# RL6955_IP_SVD register map
Vendor: Realtek
Registers are 32-bit, read-write, reset 0x0 unless marked. A register's access mark holds for its fields unless they carry their own. Offsets are from the block's base; [hi:lo] are bit positions; {n}, {i} and the like mark numbered series.

## CMP_REG
Base 0x4100A800
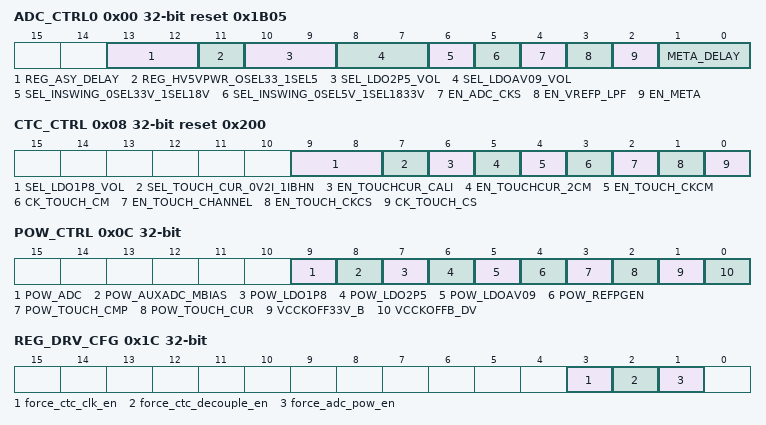
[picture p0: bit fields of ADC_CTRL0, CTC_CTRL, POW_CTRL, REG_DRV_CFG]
0x00 ADC_CTRL0 reset 0x1B05
  [13:12] REG_ASY_DELAY — Asy SAR ADC compare time. Control the delay of the comparator. If the comparator fails to produce a result for a long time, it will force the output of the result. 00:Fast; 01: 10: 11:Slow:
  [11] REG_HV5VPWR_OSEL33_1SEL5 — This Reg is used to inform Analog HV5V's PAD whether it is a true 5V voltage. It is flexible for some applications where the 5V PAD is connected to 3.3V. HV5V PAD power is 3.3V or 5V signal to Aphy.
  [10:9] SEL_LDO2P5_VOL — 00:2.125V 01:2.25V 10:2.375V 11:2.50V AIF default 01:2.25V
  [8:7] SEL_LDOAV09_VOL — AUX ADC 0.9V LDO voltage: 00:0.85V 01:0.9V 10:0.95V (default) 11:1.0V AIF default 10:0.95V;
  [6] SEL_INSWING_0SEL33V_1SEL18V — 0:ADC Input Full swing is 3.3V; 1:ADC Input Full swing is 1.8V; AIF default 0; Each CH is independent
  [5] SEL_INSWING_0SEL5V_1SEL1833V — 0 :ADC Input Full swing is 5V; 1: The input range depends on SEL_INSWING_0SEL33V_1SEL18V AIF default 0: Each CH is independent
  [4] EN_ADC_CKS — EN_ADC_CKS = 0,ADC_CKS=0 or 1,ADC always Stop to Sample State; EN_ADC_CKS = 1,ADC_CKS=1,ADC Sample State; EN_ADC_CKS = 1,ADC_CKS=0,ADC Sample Finish,ADC compare start; AIF default 1;
  [3] EN_VREFP_LPF — When 0.AUX ADC Reference LPF disable; When 1,AUX ADC Reference LPF enable; AIF default 1;
  [2] EN_META — EN_META = 1, When ADC compare not finish,force comparator to 0; EN_META = 0, Do nothing; AIF default 1;
  [1:0] META_DELAY — EN_META=1,When ADC compare not finish,force comparator to 0; META_DELAY select the delay to force comparator to 0; AIF default 01;
0x04 ADC_CTRL1 reset 0x4
  [3:0] SEL_VREFP_VOL — AUX ADC Vrefp voltage: 0000:1.45V 0001:1.50V 0010:1.55V 0011:1.60V 0100:1.65V 0101:1.70V 0110:1.75V 0111:1.80V 1000:1.85V 1001:1.875V 1010:1.90V 1011:1.95V 1100:2.00V 1101:2.05V 1110:2.10V 1111:2.15V Cs * VIN = 8C * Vrefp 3C * 5V = 8C * 1.875V 4C * 3.3V = 8C * 1.65V 8C * 1.8V = 8C * 1.8V AIF default 0100: 1.65V;
0x08 CTC_CTRL reset 0x200
  [9:8] SEL_LDO1P8_VOL — 00:1.65V 01:1.70V 10:1.75V 11:1.80V AIF default 10:1.75V;
  [7] SEL_TOUCH_CUR_0V2I_1IBHN — When 0 Touch compensate current can be VCVS current When 1 Touch compensate current use constant current AIF default 0: Use VCVS current
  [6] EN_TOUCHCUR_CALI — 1: Touch V2I Current Input Voltage use VDD_TOUCH 1.8V, not use Cm voltage, Can test Cm current for calibration; 0: Touch V2I Current Input Voltage use Cm voltage; AIF default 0: Not in Calibration state;
  [5] EN_TOUCHCUR_2CM — 1: EN Touch Compensate Current to 2.2nF Cap CM; 0: Disable Touch Compensate Current to 2.2nF Cap CM; AIF default 1;
  [4] EN_TOUCH_CKCM — EN_TOUCH_CKCM=0,Or TOUCH_CKCM=0, Touch CM not reset to VLDO_1P8; EN_TOUCH_CKCM=1,And TOUCH_CKCM=1,Touch CM reset to VLDO_1P8; AIF default 1;
  [3] CK_TOUCH_CM — When 1,Touch Cm connect to VDD_Touch 1.8V; When 0,Touch Cm dis-connect to VDD_Touch 1.8V;
  [2] EN_TOUCH_CHANNEL — EN_TOUCH_CHANNEL =0,All Touch channel not work, Cs not to GND also not to CM; EN_TOUCH_CHANNEL =1,TOUCH_LANE_SEL<3:0>select Touch Lane to Cs and CM; AIF default 1;
  [1] EN_TOUCH_CKCS — EN_TOUCH_CKCS=0,OR TOUCH_CKCS=0,Touch CS reset to GND; EN_TOUCH_CKCS=1,And TOUCH_CKCS=1,Touch CS set to CM; AIF default 1;
  [0] CK_TOUCH_CS — When 0,Touch Cs to GND; When 1,Touch Cs to Cm;
0x0C POW_CTRL
  [9] POW_ADC — POW_ADC =0.AUX ADC off; POW_ADC =1,AUX ADC on; AIF default 1;
  [8] POW_AUXADC_MBIAS — POW_ADC_MBIAS=0,AUX ADC and Touch bias current all off; POW_ADC_MBIAS=1,AUX ADC and Touch bias current on; AIF default 1;
  [7] POW_LDO1P8 — 1:Pow Touch LDO 1.8V VDD_TOUCH; 0:Off Touch LDO 1.8V VDD_TOUCH; AIF default 1:Pow on Touch LDO 1.8V;
  [6] POW_LDO2P5 — 1:AUX_ADC 2.5V LDO on; 0:AUX_ADC 2.5V LDO off; AIF default1;
  [5] POW_LDOAV09 — 1:AUX_ADC 0.9V LDO on; 0:AUX_ADC 0.9V LDO off; AIF default 1;
  [4] POW_REFPGEN — 1:AUX_ADC Reference on; 0:AUX_ADC Reference off; AIF default1;
  [3] POW_TOUCH_CMP — 1:Touch Comparator on; 0:Touch Comparator off; AIF default0;
  [2] POW_TOUCH_CUR — 1:Touch compensate Current on; 0:Touch compensate Current off; AIF default0;
  [1] VCCKOFF33V_B — When 0,Internal DVDD power off, All ADC and Touch off;
  [0] VCCKOFFB_DV — When 0,Internal DVDD power off, All ADC and Touch off;
0x10 CTC_ONLY0
  [3:0] TOUCH_LANE_SEL — Touch Lane selection: 0000: lane0; ...... 1111: lane15;
0x14 CTC_ONLY1 reset 0x8
  [4:0] SEL_TOUCH_CUR — Touch compensate current: When Cm 1800mV example: 50uA+<4:0>*5uA: Current = (50uA +<4:0>*5uA)*(Vcm/180K)/10uA; AIF default 01000,current 80uA;
0x18 CTC_ONLY2 reset 0x4
  [2:0] SEL_TOUCHCMP_VREF — Touch Comparator Vref: 000:0.5V 001:0.525V 010:0.55V 011:0.575v 100:0.60V 101:0.625V 110:0.65V 111:0.675V AIF default 100:0.6V;
0x1C REG_DRV_CFG
  [3] force_ctc_clk_en — In CTC decoupling mode, the CK_TOUCH_CS clock signal is continuously provided by the digital circuit.
  [2] force_ctc_decouple_en — Enable CTC decoupling mode, the CTC interface signal will be controlled by software
  [1] force_adc_pow_en — Enable ADC decoupling mode, the ADC power signal will be controlled by software
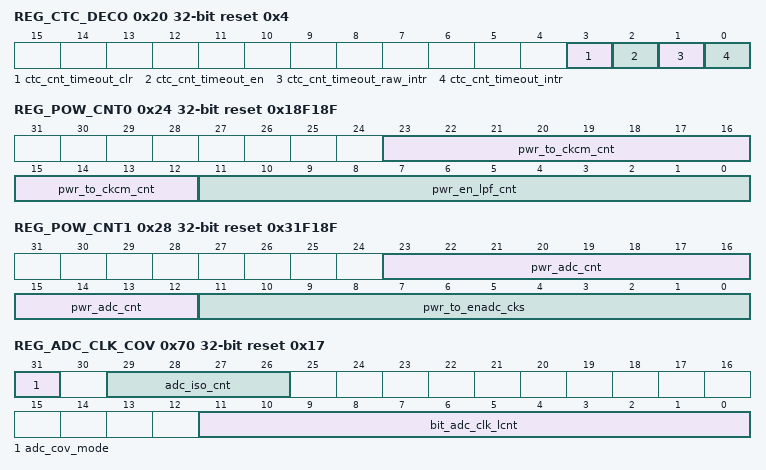
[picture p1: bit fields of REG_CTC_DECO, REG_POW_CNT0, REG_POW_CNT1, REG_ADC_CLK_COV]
0x20 REG_CTC_DECO access per field reset 0x4
  [3] ctc_cnt_timeout_clr rw — intr crean signal
  [2] ctc_cnt_timeout_en rw — intr enable
  [1] ctc_cnt_timeout_raw_intr ro — raw intr
  [0] ctc_cnt_timeout_intr ro — An interrupt is triggered when the timer reaches the ch_Sc_times
0x24 REG_POW_CNT0 reset 0x18F18F
  [23:12] pwr_to_ckcm_cnt — The delay time between pow_ldo1p8 and ck_touch_cm
  [11:0] pwr_en_lpf_cnt — The delay time between pow_mbias and en_vrefp_lpf
0x28 REG_POW_CNT1 reset 0x31F18F
  [23:12] pwr_adc_cnt — The delay time between pow_adc and ck_ad
  [11:0] pwr_to_enadc_cks — The delay time between pow_adc and en_adc_cks
{0x30+4i} REG_ADC_CLK_HCNT{i}_DIV reset 0x13 (i=0..15) — ADC Channel Clock Divider Register
  [11:0] bit_adc_clk_hcnt{i} — This field defines clock driver high level of chn in ADC module. high level =( bit_adc_clk_hcnt{i}+1) * ip_clk period . hcnt11-13 is rsvd.
0x70 REG_ADC_CLK_COV reset 0x17
  [31] adc_cov_mode — 0: convert time is 500ns 1: convert time is 700ns
  [29:26] adc_iso_cnt — Control the time of iso ch. if adc_iso_cnt is 0, iso_ch will disable
  [11:0] bit_adc_clk_lcnt — This field defines clock driver lower level of chn in ADC module.when source clock is 4M, the duration of low level need >=2 for timing req.(>=0.5us) lower level =bit_adc_clk_lcnt* ip_clk period
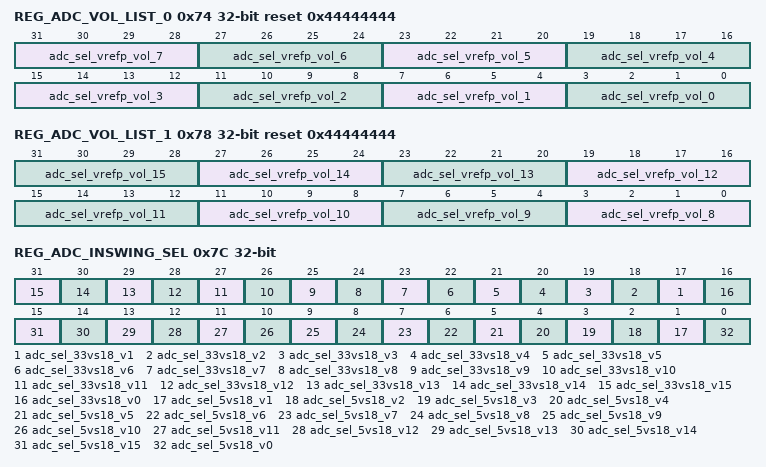
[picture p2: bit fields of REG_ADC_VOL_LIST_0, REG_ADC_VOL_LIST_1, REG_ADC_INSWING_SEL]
0x74 REG_ADC_VOL_LIST_0 reset 0x44444444
  [4n+3:4n] adc_sel_vrefp_vol_{n} (n=1..7) — Refer to adc_sel_vrefp_vol_0
  [3:0] adc_sel_vrefp_vol_0 — AUX ADC Vrefp voltage: 0000:1.45V 0001:1.50V 0010:1.55V 0011:1.60V 0100:1.65V 0101:1.70V 0110:1.75V 0111:1.80V 1000:1.85V 1001:1.875V 1010:1.90V 1011:1.95V 1100:2.00V 1101:2.05V 1110:2.10V 1111:2.15V Cs * VIN = 8C * Vrefp 3C * 5V = 8C * 1.875V 4C * 3.3V = 8C * 1.65V 8C * 1.8V = 8C * 1.8V AIF default 0100: 1.65V;
0x78 REG_ADC_VOL_LIST_1 reset 0x44444444
  [4n-29:4n-32] adc_sel_vrefp_vol_{n} (n=8..15) — Refer to adc_sel_vrefp_vol_0
0x7C REG_ADC_INSWING_SEL
  [n+16] adc_sel_33vs18_v{n} (n=1..15) — Refer to adc_sel_33vs18_v0
  [16] adc_sel_33vs18_v0 — 0:ADC Input Full swing is 3.3V; 1:ADC Input Full swing is 1.8V; AIF default 0; Each CH is independent
  [n] adc_sel_5vs18_v{n} (n=1..15) — Refer to adc_sel_5vs18_v0
  [0] adc_sel_5vs18_v0 — 0 :ADC Input Full swing is 5V; 1: The input range depends on adc_sel_33vs18_v0 AIF default 0: Each CH is independent
0x80 REG_DUMMY — Dummy Register
